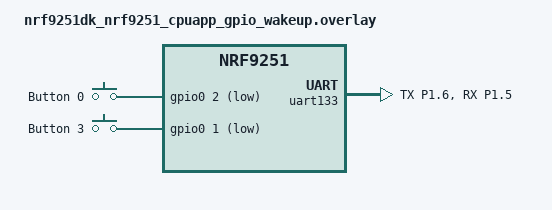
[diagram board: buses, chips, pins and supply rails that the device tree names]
/*
 * Copyright (c) 2026 Nordic Semiconductor ASA
 *
 * SPDX-License-Identifier: LicenseRef-Nordic-5-Clause
 */

/* Test requires loopback
 * from RXD0 (P1.05) to P0.02
 */

/ {
	/*
	 * Swap button0 with button3
	 * (P0.01 is already used in CI setup for other purposes).
	 */
	buttons {
		compatible = "gpio-keys";

		button0: button_0 {
			gpios = <&gpio0 2 (GPIO_PULL_UP | GPIO_ACTIVE_LOW)>;
			label = "Button 0";
		};

		button3: button_3 {
			gpios = <&gpio0 1 (GPIO_PULL_UP | GPIO_ACTIVE_LOW)>;
			label = "Button 3";
		};
	};
};

/* Disable UART flow-control. This is just to unlock debugger chip.
 * When debugger chip receives data from PC it passes data to nrf9251 P1.05.
 * Nrf9251 UART peripheral ignores transmission.
 * External GPIO loopback shorts P1.05 with P0.02 (button_0).
 * UART signal is treated as button press and release.
 */
&pinctrl {
	uart133_default_alt: uart133_default_alt {
		group1 {
			psels = <NRF_PSEL(UART_TX, 1, 6)>;
		};

		group3 {
			psels = <NRF_PSEL(UART_RX, 1, 5)>;
			bias-pull-up;
		};
	};

	uart133_sleep_alt: uart133_sleep_alt {
		group1 {
			psels = <NRF_PSEL(UART_TX, 1, 6)>,
				<NRF_PSEL(UART_RX, 1, 5)>;
			low-power-enable;
		};
	};
};

&uart133 {
	pinctrl-0 = <&uart133_default_alt>;
	pinctrl-1 = <&uart133_sleep_alt>;
	pinctrl-names = "default", "sleep";
	/delete-property/ hw-flow-control;
};
